# STM32H745BGT6@M4 register map
File version: 1.0
Registers are 32-bit, access not given, reset 0x0 unless marked. A register's access mark holds for its fields unless they carry their own. Offsets are from the block's base; [hi:lo] are bit positions; {n}, {i} and the like mark numbered series.

## FDCAN1
Base 0x4000A000
Same registers: FDCAN2 0x4000A400
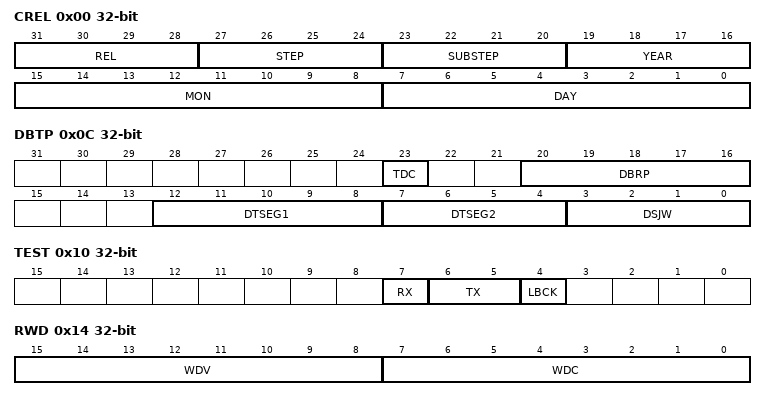
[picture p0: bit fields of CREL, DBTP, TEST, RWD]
0x00 CREL
  [31:28] REL, [27:24] STEP, [23:20] SUBSTEP, [19:16] YEAR, [15:8] MON, [7:0] DAY
0x04 ENDN
  [31:0] ETV
0x0C DBTP
  [23] TDC, [20:16] DBRP, [12:8] DTSEG1, [7:4] DTSEG2, [3:0] DSJW
0x10 TEST
  [7] RX, [6:5] TX, [4] LBCK
0x14 RWD
  [15:8] WDV, [7:0] WDC
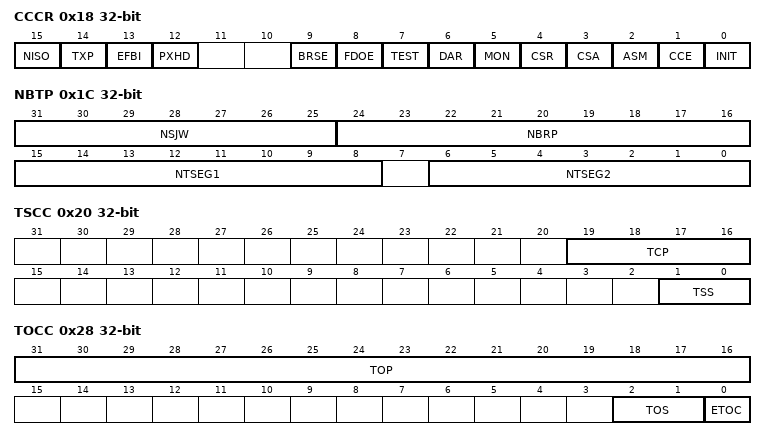
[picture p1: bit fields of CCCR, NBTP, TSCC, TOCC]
0x18 CCCR
  [15] NISO, [14] TXP, [13] EFBI, [12] PXHD, [9] BRSE, [8] FDOE, [7] TEST, [6] DAR, [5] MON, [4] CSR, [3] CSA, [2] ASM, [1] CCE, [0] INIT
0x1C NBTP
  [31:25] NSJW, [24:16] NBRP, [15:8] NTSEG1, [6:0] NTSEG2
0x20 TSCC
  [19:16] TCP, [1:0] TSS
0x24 TSCV
  [15:0] TSC
0x28 TOCC
  [31:16] TOP, [2:1] TOS, [0] ETOC
0x2C TOCV
  [15:0] TOC
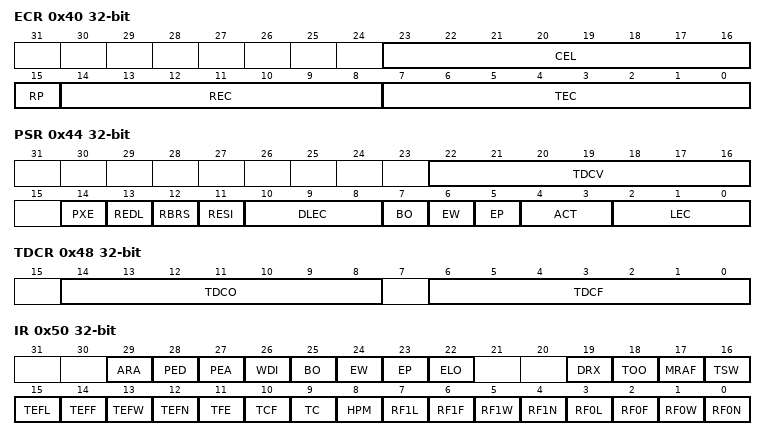
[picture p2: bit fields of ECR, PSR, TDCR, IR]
0x40 ECR
  [23:16] CEL, [15] RP, [14:8] REC, [7:0] TEC
0x44 PSR
  [22:16] TDCV, [14] PXE, [13] REDL, [12] RBRS, [11] RESI, [10:8] DLEC, [7] BO, [6] EW, [5] EP, [4:3] ACT, [2:0] LEC
0x48 TDCR
  [14:8] TDCO, [6:0] TDCF
0x50 IR
  [29] ARA, [28] PED, [27] PEA, [26] WDI, [25] BO, [24] EW, [23] EP, [22] ELO, [19] DRX, [18] TOO, [17] MRAF, [16] TSW, [15] TEFL, [14] TEFF, [13] TEFW, [12] TEFN, [11] TFE, [10] TCF, [9] TC, [8] HPM, [7] RF1L, [6] RF1F, [5] RF1W, [4] RF1N, [3] RF0L, [2] RF0F, [1] RF0W, [0] RF0N
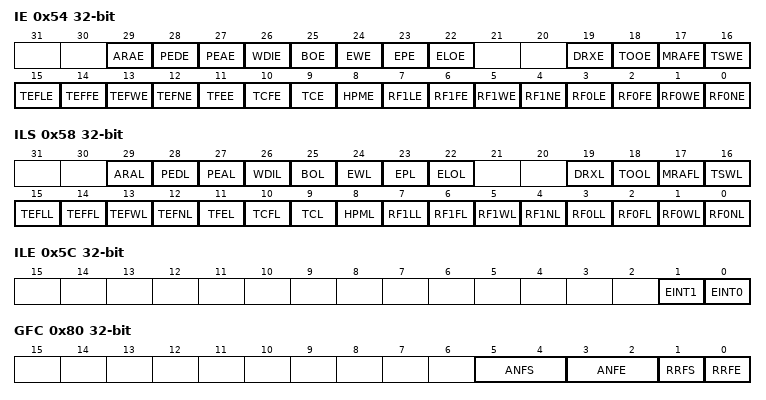
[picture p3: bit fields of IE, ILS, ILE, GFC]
0x54 IE
  [29] ARAE, [28] PEDE, [27] PEAE, [26] WDIE, [25] BOE, [24] EWE, [23] EPE, [22] ELOE, [19] DRXE, [18] TOOE, [17] MRAFE, [16] TSWE, [15] TEFLE, [14] TEFFE, [13] TEFWE, [12] TEFNE, [11] TFEE, [10] TCFE, [9] TCE, [8] HPME, [7] RF1LE, [6] RF1FE, [5] RF1WE, [4] RF1NE, [3] RF0LE, [2] RF0FE, [1] RF0WE, [0] RF0NE
0x58 ILS
  [29] ARAL, [28] PEDL, [27] PEAL, [26] WDIL, [25] BOL, [24] EWL, [23] EPL, [22] ELOL, [19] DRXL, [18] TOOL, [17] MRAFL, [16] TSWL, [15] TEFLL, [14] TEFFL, [13] TEFWL, [12] TEFNL, [11] TFEL, [10] TCFL, [9] TCL, [8] HPML, [7] RF1LL, [6] RF1FL, [5] RF1WL, [4] RF1NL, [3] RF0LL, [2] RF0FL, [1] RF0WL, [0] RF0NL
0x5C ILE
  [1] EINT1, [0] EINT0
0x80 GFC
  [5:4] ANFS, [3:2] ANFE, [1] RRFS, [0] RRFE
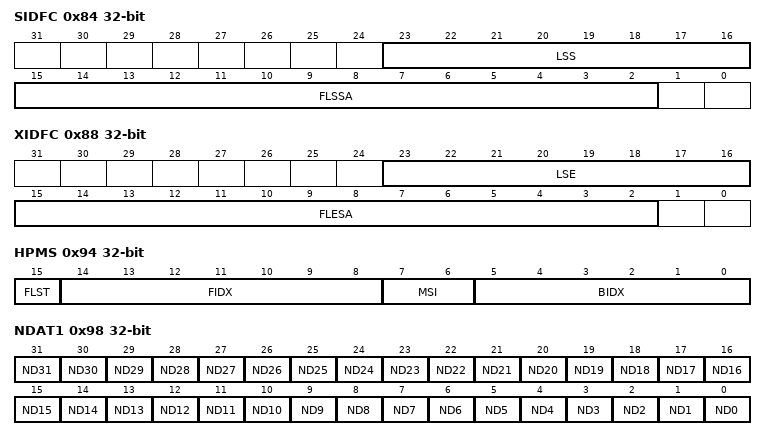
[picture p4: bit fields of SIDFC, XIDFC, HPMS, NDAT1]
0x84 SIDFC
  [23:16] LSS, [15:2] FLSSA
0x88 XIDFC
  [23:16] LSE, [15:2] FLESA
0x90 XIDAM
  [28:0] EIDM
0x94 HPMS
  [15] FLST, [14:8] FIDX, [7:6] MSI, [5:0] BIDX
0x98 NDAT1
  [n] ND{n} (n=0..31)
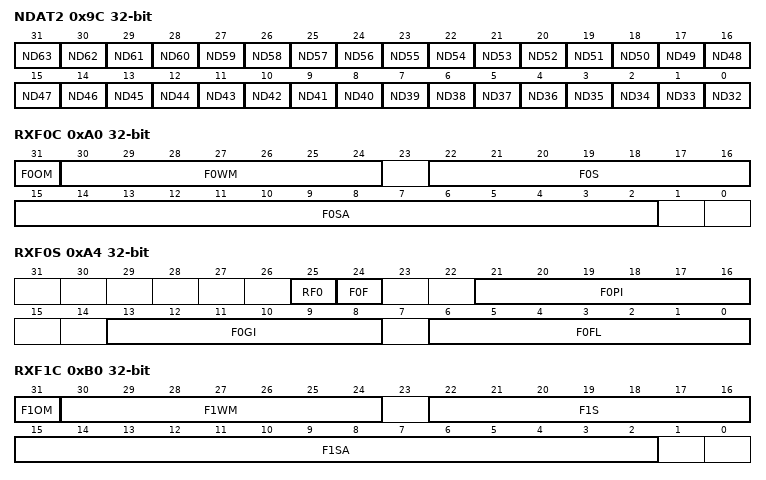
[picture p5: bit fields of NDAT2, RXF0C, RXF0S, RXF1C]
0x9C NDAT2
  [n-32] ND{n} (n=32..63)
0xA0 RXF0C
  [31] F0OM, [30:24] F0WM, [22:16] F0S, [15:2] F0SA
0xA4 RXF0S
  [25] RF0, [24] F0F, [21:16] F0PI, [13:8] F0GI, [6:0] F0FL
0xA8 RXF0A
  [5:0] F0AI
0xAC RXBC
  [15:2] RBSA
0xB0 RXF1C
  [31] F1OM, [30:24] F1WM, [22:16] F1S, [15:2] F1SA
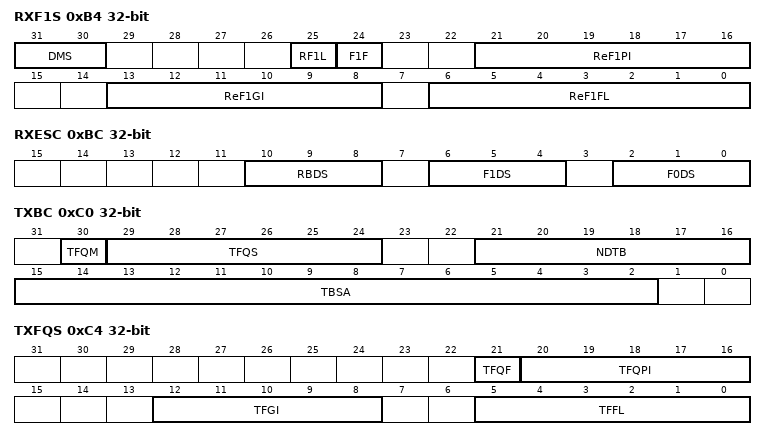
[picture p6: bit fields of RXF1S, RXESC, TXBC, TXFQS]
0xB4 RXF1S
  [31:30] DMS, [25] RF1L, [24] F1F, [21:16] ReF1PI, [13:8] ReF1GI, [6:0] ReF1FL
0xB8 RXF1A
  [5:0] F1AI
0xBC RXESC
  [10:8] RBDS, [6:4] F1DS, [2:0] F0DS
0xC0 TXBC
  [30] TFQM, [29:24] TFQS, [21:16] NDTB, [15:2] TBSA
0xC4 TXFQS
  [21] TFQF, [20:16] TFQPI, [12:8] TFGI, [5:0] TFFL
0xC8 TXESC
  [2:0] TBDS
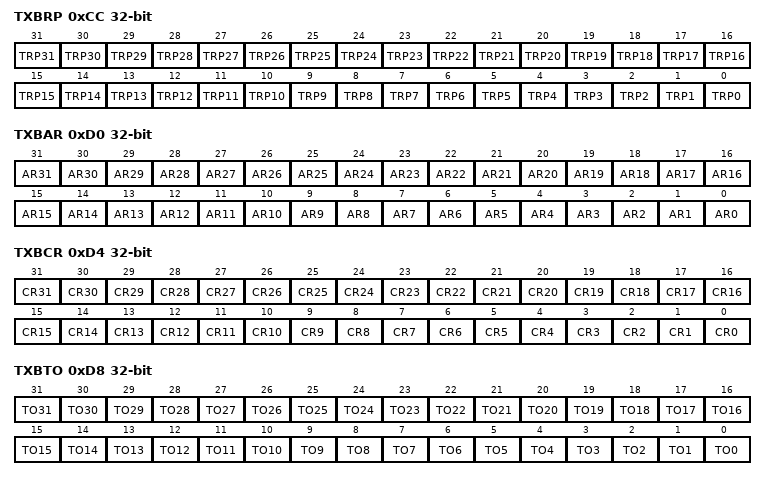
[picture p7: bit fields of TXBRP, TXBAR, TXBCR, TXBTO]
0xCC TXBRP
  [n] TRP{n} (n=0..31)
0xD0 TXBAR
  [n] AR{n} (n=0..31)
0xD4 TXBCR
  [n] CR{n} (n=0..31)
0xD8 TXBTO
  [n] TO{n} (n=0..31)
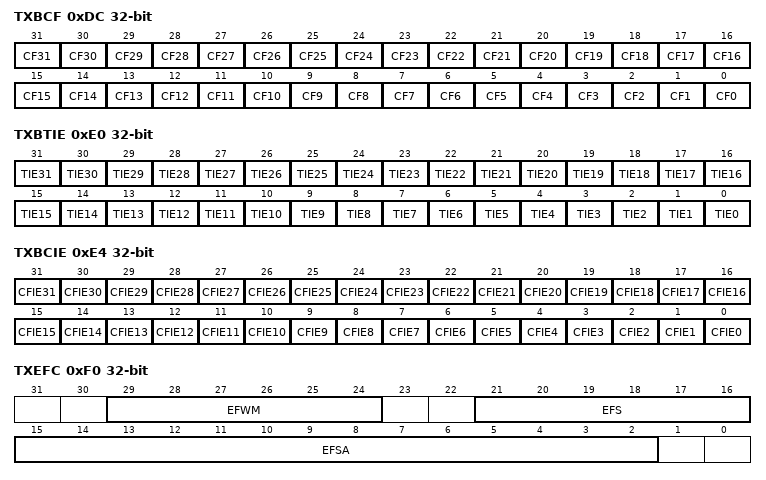
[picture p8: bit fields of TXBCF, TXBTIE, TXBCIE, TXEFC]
0xDC TXBCF
  [n] CF{n} (n=0..31)
0xE0 TXBTIE
  [n] TIE{n} (n=0..31)
0xE4 TXBCIE
  [n] CFIE{n} (n=0..31)
0xF0 TXEFC
  [29:24] EFWM, [21:16] EFS, [15:2] EFSA
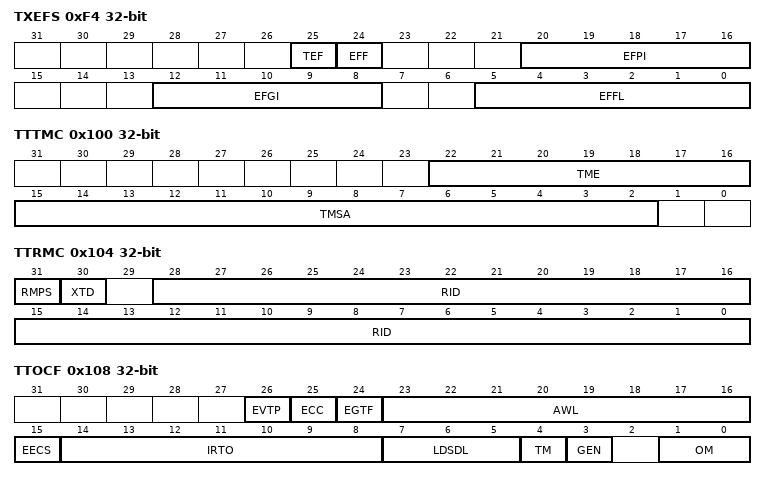
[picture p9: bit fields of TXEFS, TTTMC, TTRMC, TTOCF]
0xF4 TXEFS
  [25] TEF, [24] EFF, [20:16] EFPI, [12:8] EFGI, [5:0] EFFL
0xF8 TXEFA
  [4:0] EFAI
0x100 TTTMC
  [22:16] TME, [15:2] TMSA
0x104 TTRMC
  [31] RMPS, [30] XTD, [28:0] RID
0x108 TTOCF
  [26] EVTP, [25] ECC, [24] EGTF, [23:16] AWL, [15] EECS, [14:8] IRTO, [7:5] LDSDL, [4] TM, [3] GEN, [1:0] OM
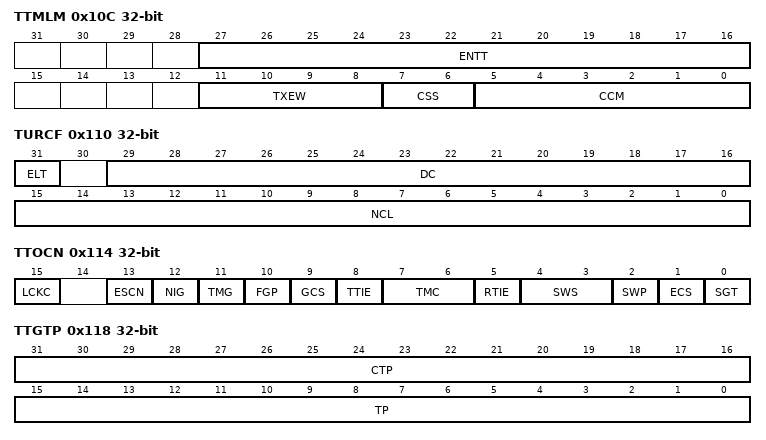
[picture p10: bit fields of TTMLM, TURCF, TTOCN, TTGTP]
0x10C TTMLM
  [27:16] ENTT, [11:8] TXEW, [7:6] CSS, [5:0] CCM
0x110 TURCF
  [31] ELT, [29:16] DC, [15:0] NCL
0x114 TTOCN
  [15] LCKC, [13] ESCN, [12] NIG, [11] TMG, [10] FGP, [9] GCS, [8] TTIE, [7:6] TMC, [5] RTIE, [4:3] SWS, [2] SWP, [1] ECS, [0] SGT
0x118 TTGTP
  [31:16] CTP, [15:0] TP
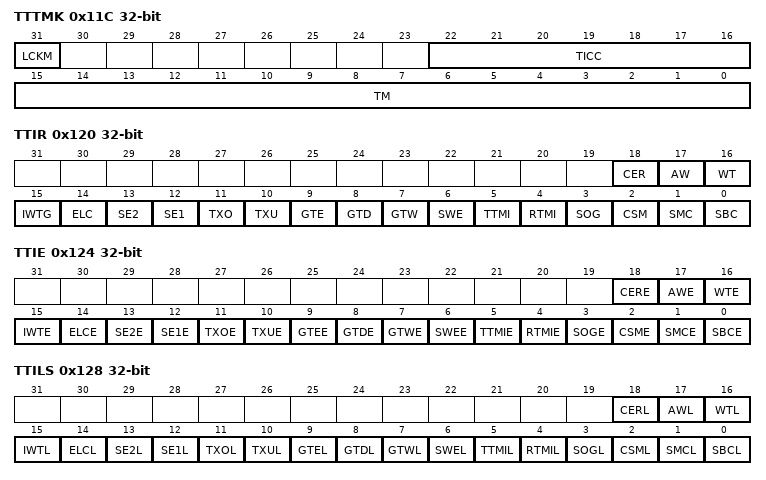
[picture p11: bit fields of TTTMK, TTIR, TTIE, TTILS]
0x11C TTTMK
  [31] LCKM, [22:16] TICC, [15:0] TM
0x120 TTIR
  [18] CER, [17] AW, [16] WT, [15] IWTG, [14] ELC, [13] SE2, [12] SE1, [11] TXO, [10] TXU, [9] GTE, [8] GTD, [7] GTW, [6] SWE, [5] TTMI, [4] RTMI, [3] SOG, [2] CSM, [1] SMC, [0] SBC
0x124 TTIE
  [18] CERE, [17] AWE, [16] WTE, [15] IWTE, [14] ELCE, [13] SE2E, [12] SE1E, [11] TXOE, [10] TXUE, [9] GTEE, [8] GTDE, [7] GTWE, [6] SWEE, [5] TTMIE, [4] RTMIE, [3] SOGE, [2] CSME, [1] SMCE, [0] SBCE
0x128 TTILS
  [18] CERL, [17] AWL, [16] WTL, [15] IWTL, [14] ELCL, [13] SE2L, [12] SE1L, [11] TXOL, [10] TXUL, [9] GTEL, [8] GTDL, [7] GTWL, [6] SWEL, [5] TTMIL, [4] RTMIL, [3] SOGL, [2] CSML, [1] SMCL, [0] SBCL
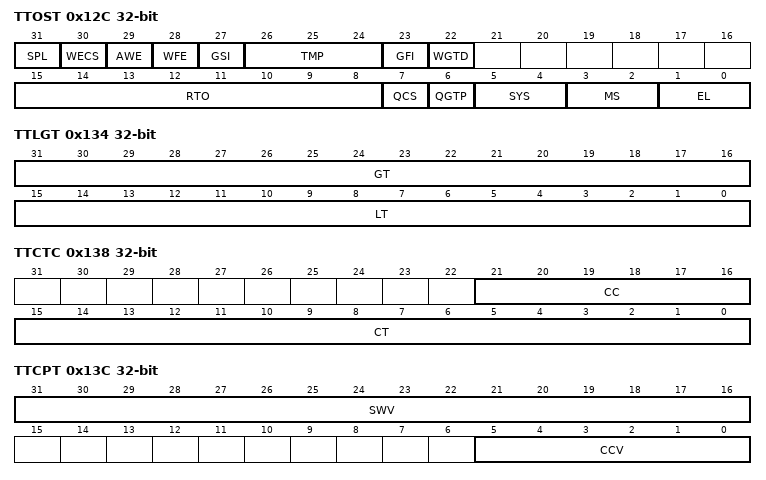
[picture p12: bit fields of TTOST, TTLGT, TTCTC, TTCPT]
0x12C TTOST
  [31] SPL, [30] WECS, [29] AWE, [28] WFE, [27] GSI, [26:24] TMP, [23] GFI, [22] WGTD, [15:8] RTO, [7] QCS, [6] QGTP, [5:4] SYS, [3:2] MS, [1:0] EL
0x130 TURNA
  [17:0] NAV
0x134 TTLGT
  [31:16] GT, [15:0] LT
0x138 TTCTC
  [21:16] CC, [15:0] CT
0x13C TTCPT
  [31:16] SWV, [5:0] CCV
0x140 TTCSM
  [15:0] CSM
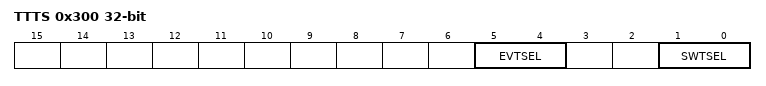
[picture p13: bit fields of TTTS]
0x300 TTTS
  [5:4] EVTSEL, [1:0] SWTSEL
